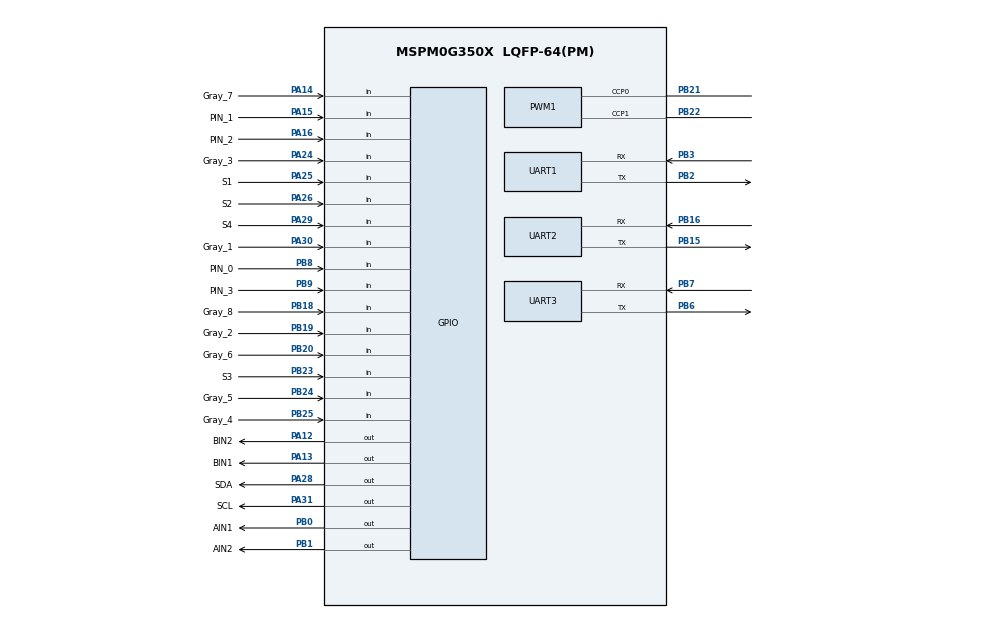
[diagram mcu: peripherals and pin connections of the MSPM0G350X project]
/**
 * @cliArgs --device "MSPM0G350X" --part "Default" --package "LQFP-64(PM)" --product "mspm0_sdk@2.10.00.04"
 * @versions {"tool":"1.26.2+4477"}
 */

/**
 * Import the modules used in this configuration.
 */
const Board  = scripting.addModule("/ti/driverlib/Board");
const GPIO   = scripting.addModule("/ti/driverlib/GPIO", {}, false);
const GPIO1  = GPIO.addInstance();
const GPIO2  = GPIO.addInstance();
const GPIO3  = GPIO.addInstance();
const GPIO4  = GPIO.addInstance();
const GPIO5  = GPIO.addInstance();
const GPIO6  = GPIO.addInstance();
const PWM    = scripting.addModule("/ti/driverlib/PWM", {}, false);
const PWM1   = PWM.addInstance();
const SYSCTL = scripting.addModule("/ti/driverlib/SYSCTL");
const TIMER  = scripting.addModule("/ti/driverlib/TIMER", {}, false);
const TIMER1 = TIMER.addInstance();
const TIMER2 = TIMER.addInstance();
const UART   = scripting.addModule("/ti/driverlib/UART", {}, false);
const UART1  = UART.addInstance();
const UART2  = UART.addInstance();
const UART3  = UART.addInstance();

/**
 * Write custom configuration values to the imported modules.
 */

GPIO1.$name                         = "GPIO_TB6612";
GPIO1.associatedPins.create(4);
GPIO1.associatedPins[0].$name       = "AIN1";
GPIO1.associatedPins[0].pin.$assign = "PB0";
GPIO1.associatedPins[1].$name       = "AIN2";
GPIO1.associatedPins[1].pin.$assign = "PB1";
GPIO1.associatedPins[2].$name       = "BIN1";
GPIO1.associatedPins[2].pin.$assign = "PA13";
GPIO1.associatedPins[3].$name       = "BIN2";
GPIO1.associatedPins[3].pin.$assign = "PA12";

GPIO2.$name                         = "GPIO_Gray";
GPIO2.associatedPins.create(8);
GPIO2.associatedPins[0].direction   = "INPUT";
GPIO2.associatedPins[0].$name       = "Gray_1";
GPIO2.associatedPins[0].pin.$assign = "PA30";
GPIO2.associatedPins[1].direction   = "INPUT";
GPIO2.associatedPins[1].$name       = "Gray_2";
GPIO2.associatedPins[1].pin.$assign = "PB19";
GPIO2.associatedPins[2].direction   = "INPUT";
GPIO2.associatedPins[2].$name       = "Gray_3";
GPIO2.associatedPins[2].pin.$assign = "PA24";
GPIO2.associatedPins[3].direction   = "INPUT";
GPIO2.associatedPins[3].$name       = "Gray_4";
GPIO2.associatedPins[3].pin.$assign = "PB25";
GPIO2.associatedPins[4].direction   = "INPUT";
GPIO2.associatedPins[4].$name       = "Gray_5";
GPIO2.associatedPins[4].pin.$assign = "PB24";
GPIO2.associatedPins[5].direction   = "INPUT";
GPIO2.associatedPins[5].$name       = "Gray_6";
GPIO2.associatedPins[5].pin.$assign = "PB20";
GPIO2.associatedPins[6].direction   = "INPUT";
GPIO2.associatedPins[6].$name       = "Gray_7";
GPIO2.associatedPins[6].pin.$assign = "PA14";
GPIO2.associatedPins[7].direction   = "INPUT";
GPIO2.associatedPins[7].$name       = "Gray_8";
GPIO2.associatedPins[7].pin.$assign = "PB18";

GPIO3.$name                         = "GPIO_OLED";
GPIO3.associatedPins.create(2);
GPIO3.associatedPins[0].$name       = "SCL";
GPIO3.associatedPins[0].pin.$assign = "PA31";
GPIO3.associatedPins[1].$name       = "SDA";
GPIO3.associatedPins[1].pin.$assign = "PA28";

GPIO4.$name                              = "GPIO_Key";
GPIO4.associatedPins.create(4);
GPIO4.associatedPins[0].direction        = "INPUT";
GPIO4.associatedPins[0].internalResistor = "PULL_UP";
GPIO4.associatedPins[0].$name            = "S1";
GPIO4.associatedPins[0].pin.$assign      = "PA25";
GPIO4.associatedPins[1].direction        = "INPUT";
GPIO4.associatedPins[1].internalResistor = "PULL_UP";
GPIO4.associatedPins[1].$name            = "S2";
GPIO4.associatedPins[1].pin.$assign      = "PA26";
GPIO4.associatedPins[2].direction        = "INPUT";
GPIO4.associatedPins[2].internalResistor = "PULL_UP";
GPIO4.associatedPins[2].$name            = "S3";
GPIO4.associatedPins[2].pin.$assign      = "PB23";
GPIO4.associatedPins[3].direction        = "INPUT";
GPIO4.associatedPins[3].internalResistor = "PULL_UP";
GPIO4.associatedPins[3].$name            = "S4";
GPIO4.associatedPins[3].pin.$assign      = "PA29";

GPIO5.$name                         = "GPIO_ENCODEA";
GPIO5.associatedPins.create(2);
GPIO5.associatedPins[0].$name       = "PIN_0";
GPIO5.associatedPins[0].direction   = "INPUT";
GPIO5.associatedPins[0].interruptEn = true;
GPIO5.associatedPins[0].polarity    = "RISE";
GPIO5.associatedPins[0].pin.$assign = "PB8";
GPIO5.associatedPins[1].$name       = "PIN_3";
GPIO5.associatedPins[1].direction   = "INPUT";
GPIO5.associatedPins[1].interruptEn = true;
GPIO5.associatedPins[1].polarity    = "RISE";
GPIO5.associatedPins[1].pin.$assign = "PB9";

GPIO6.$name                         = "GPIO_ENCODEB";
GPIO6.associatedPins.create(2);
GPIO6.associatedPins[0].$name       = "PIN_1";
GPIO6.associatedPins[0].direction   = "INPUT";
GPIO6.associatedPins[0].interruptEn = true;
GPIO6.associatedPins[0].polarity    = "RISE";
GPIO6.associatedPins[0].pin.$assign = "PA15";
GPIO6.associatedPins[1].$name       = "PIN_2";
GPIO6.associatedPins[1].direction   = "INPUT";
GPIO6.associatedPins[1].interruptEn = true;
GPIO6.associatedPins[1].polarity    = "RISE";
GPIO6.associatedPins[1].pin.$assign = "PA16";

PWM1.$name                              = "PWM_MOTOR";
PWM1.dutyArgs                           = "[25,25,0,0]";
PWM1.timerCount                         = 1600;
PWM1.timerStartTimer                    = true;
PWM1.peripheral.$assign                 = "TIMG8";
PWM1.peripheral.ccp0Pin.$assign         = "PB21";
PWM1.peripheral.ccp1Pin.$assign         = "PB22";
PWM1.PWM_CHANNEL_0.$name                = "ti_driverlib_pwm_PWMTimerCC0";
PWM1.PWM_CHANNEL_1.$name                = "ti_driverlib_pwm_PWMTimerCC1";
PWM1.ccp0PinConfig.$name                = "ti_driverlib_gpio_GPIOPinGeneric0";
PWM1.ccp0PinConfig.direction            = scripting.forceWrite("OUTPUT");
PWM1.ccp0PinConfig.hideOutputInversion  = scripting.forceWrite(false);
PWM1.ccp0PinConfig.onlyInternalResistor = scripting.forceWrite(false);
PWM1.ccp0PinConfig.passedPeripheralType = scripting.forceWrite("Digital");
PWM1.ccp1PinConfig.$name                = "ti_driverlib_gpio_GPIOPinGeneric1";
PWM1.ccp1PinConfig.direction            = scripting.forceWrite("OUTPUT");
PWM1.ccp1PinConfig.hideOutputInversion  = scripting.forceWrite(false);
PWM1.ccp1PinConfig.onlyInternalResistor = scripting.forceWrite(false);
PWM1.ccp1PinConfig.passedPeripheralType = scripting.forceWrite("Digital");

SYSCTL.forceDefaultClkConfig = true;

TIMER1.$name = "TIMER_0";

TIMER2.$name = "TIMER_1";

UART1.$name                            = "UART_GYRO";
UART1.targetBaudRate                   = 115200;
UART1.enabledInterrupts                = ["RX"];
UART1.peripheral.$assign               = "UART3";
UART1.peripheral.rxPin.$assign         = "PB3";
UART1.peripheral.txPin.$assign         = "PB2";
UART1.txPinConfig.$name                = "ti_driverlib_gpio_GPIOPinGeneric2";
UART1.txPinConfig.direction            = scripting.forceWrite("OUTPUT");
UART1.txPinConfig.hideOutputInversion  = scripting.forceWrite(false);
UART1.txPinConfig.onlyInternalResistor = scripting.forceWrite(false);
UART1.txPinConfig.passedPeripheralType = scripting.forceWrite("Digital");
UART1.rxPinConfig.$name                = "ti_driverlib_gpio_GPIOPinGeneric3";
UART1.rxPinConfig.hideOutputInversion  = scripting.forceWrite(false);
UART1.rxPinConfig.onlyInternalResistor = scripting.forceWrite(false);
UART1.rxPinConfig.passedPeripheralType = scripting.forceWrite("Digital");

UART2.$name                            = "UART_dianji";
UART2.targetBaudRate                   = 115200;
UART2.peripheral.rxPin.$assign         = "PB16";
UART2.peripheral.txPin.$assign         = "PB15";
UART2.txPinConfig.$name                = "ti_driverlib_gpio_GPIOPinGeneric4";
UART2.txPinConfig.direction            = scripting.forceWrite("OUTPUT");
UART2.txPinConfig.hideOutputInversion  = scripting.forceWrite(false);
UART2.txPinConfig.onlyInternalResistor = scripting.forceWrite(false);
UART2.txPinConfig.passedPeripheralType = scripting.forceWrite("Digital");
UART2.rxPinConfig.$name                = "ti_driverlib_gpio_GPIOPinGeneric5";
UART2.rxPinConfig.hideOutputInversion  = scripting.forceWrite(false);
UART2.rxPinConfig.onlyInternalResistor = scripting.forceWrite(false);
UART2.rxPinConfig.passedPeripheralType = scripting.forceWrite("Digital");

UART3.$name                            = "UART_Camera";
UART3.targetBaudRate                   = 115200;
UART3.enabledInterrupts                = ["RX"];
UART3.peripheral.rxPin.$assign         = "PB7";
UART3.peripheral.txPin.$assign         = "PB6";
UART3.txPinConfig.$name                = "ti_driverlib_gpio_GPIOPinGeneric6";
UART3.txPinConfig.direction            = scripting.forceWrite("OUTPUT");
UART3.txPinConfig.hideOutputInversion  = scripting.forceWrite(false);
UART3.txPinConfig.onlyInternalResistor = scripting.forceWrite(false);
UART3.txPinConfig.passedPeripheralType = scripting.forceWrite("Digital");
UART3.rxPinConfig.$name                = "ti_driverlib_gpio_GPIOPinGeneric7";
UART3.rxPinConfig.hideOutputInversion  = scripting.forceWrite(false);
UART3.rxPinConfig.onlyInternalResistor = scripting.forceWrite(false);
UART3.rxPinConfig.passedPeripheralType = scripting.forceWrite("Digital");

/**
 * Pinmux solution for unlocked pins/peripherals. This ensures that minor changes to the automatic solver in a future
 * version of the tool will not impact the pinmux you originally saw.  These lines can be completely deleted in order to
 * re-solve from scratch.
 */
Board.peripheral.$suggestSolution          = "DEBUGSS";
Board.peripheral.swclkPin.$suggestSolution = "PA20";
Board.peripheral.swdioPin.$suggestSolution = "PA19";
SYSCTL.peripheral.$suggestSolution         = "SYSCTL";
TIMER1.peripheral.$suggestSolution         = "TIMA1";
TIMER2.peripheral.$suggestSolution         = "TIMA0";
UART2.peripheral.$suggestSolution          = "UART2";
UART3.peripheral.$suggestSolution          = "UART1";
